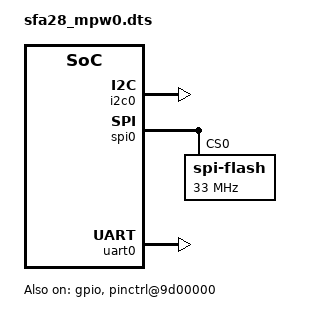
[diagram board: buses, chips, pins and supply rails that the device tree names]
/dts-v1/;

/memreserve/ 0x00000000 0x00001000;	/* Exception vectors */
/memreserve/ 0x000f0000 0x00010000;	/* PIIX4 ISA memory */

/ {
	#address-cells = <1>;
	#size-cells = <1>;
	compatible = "sf,sfa28";

	chosen {
		stdout-path = &uart0;
		tick-timer = &timer0;
	};

	aliases {
		spi0 = &spi0;
		i2c0 = &i2c0;
	};

	palmbus@b0000000 {
		compatible = "simple-bus";
		reg = <0xb0000000 0x10000000>;
		#address-cells = <1>;
		#size-cells = <1>;
		ranges = <0x0 0xb0000000 0xfffffff>;

		u-boot,dm-pre-reloc;

		gdma@1800000{
			compatible = "gdma";
			reg = <0x1800000 0x100>;
		};

		i2c0: i2c@8100000 {
			#address-cells = <1>;
			#size-cells = <1>;
			compatible = "siflower,sfax8-i2c";
			reg = <0x8100000 0x1000>;
			clock = <100000000>;
			#status = "disabled";

		};

		spi0: spi@8202000 {
			#address-cells = <1>;
			#size-cells = <0>;
			compatible = "siflower,armada-a28-spi";
			reg = <0x8202000 0x1000>;
			reg-shift = <0>;
			clock = <100000000>;
			spi-max-frequency = <33000000>;
			cs0-gpios = <&gpio 8 1>;
			u-boot,dm-pre-reloc;

			spi-flash@0 {
				compatible = "spi-flash";
				reg = <0>;
				spi-max-frequency = <33000000>;
				u-boot,dm-pre-reloc;
			};
		};

		uart0: serial@8300000 {
			compatible = "mips,sfax8";
			u-boot,dm-pre-reloc;

			reg = <0x8300000 0x1000>;
			reg-shift = <0>;

			clock = <125000000>;
			skip_init = <0>;
		};

		timer0: timer0@8600000{
			compatible = "siflower,timer0";
			clock-frequency=<100000000>;
			reg = <0x8600000 0x1000>;
		};


		gpio:gpio@9d00000 {
			compatible = "siflower,sfax8-gpio";
			reg = <0x9d00000 0x100000>, /* gpio base*/
				  <0x9e30000 0x100000>;/* pad base */
			reg-names = "gpio_base","pad_base";

			ranges = <0 0x9e30000 0x100000>;
			gpio-controller;
			#gpio-cells = <2>;
			#address-cells = <1>;
			#size-cells = <1>;
			status = "okay";
			u-boot,dm-pre-reloc;
		};

		pinctrl@9d00000 {
			compatible = "siflower,sfa28-pinctrl";
			reg = <0x9d00000 0x100000>, /* gpio base*/
				  <0x9e30000 0x100000>;/* pad base */
			reg-names = "gpio_base","pad_base";
			ranges = <0 0x9e30000 0x100000>;
			#address-cells = <1>;
			#size-cells = <1>;
			status = "okay";
			u-boot,dm-pre-reloc;
		};
	};
};

